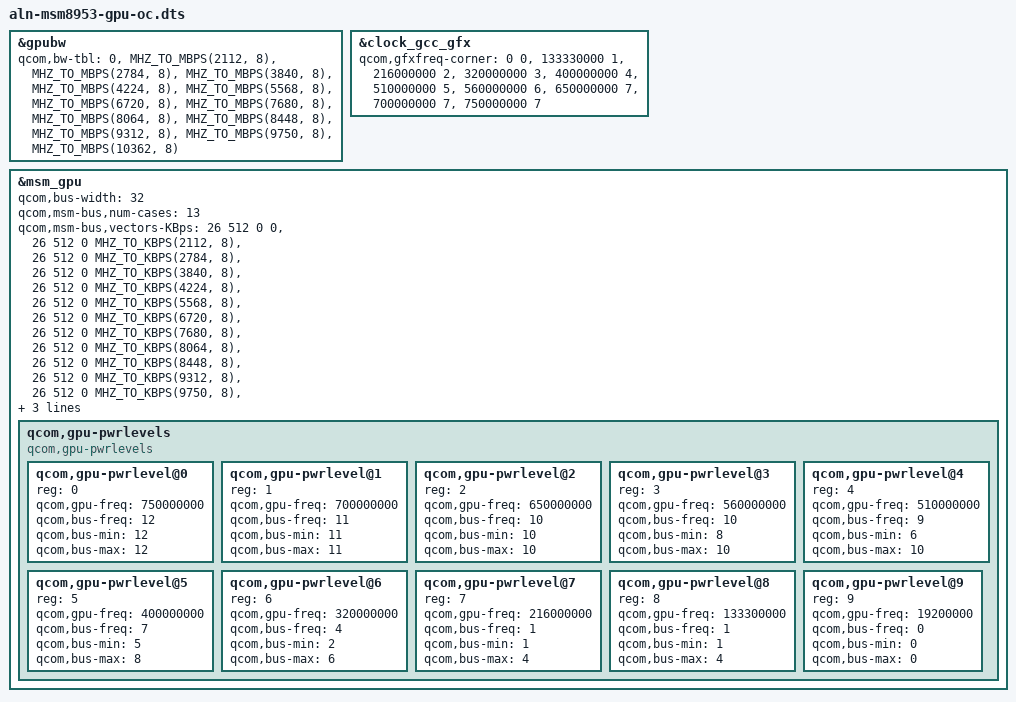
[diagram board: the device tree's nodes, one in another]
/*
 * Copyright (c) 2015-2017, The Linux Foundation. All rights reserved.
 * Copyright (C) 2019 XiaoMi, Inc.
 *
 * This program is free software; you can redistribute it and/or modify
 * it under the terms of the GNU General Public License version 2 and
 * only version 2 as published by the Free Software Foundation.
 *
 * This program is distributed in the hope that it will be useful,
 * but WITHOUT ANY WARRANTY; without even the implied warranty of
 * MERCHANTABILITY or FITNESS FOR A PARTICULAR PURPOSE.  See the
 * GNU General Public License for more details.
 */

/dts-v1/;

#define MHZ_TO_MBPS(mhz, w) ((mhz * 1000000 * w) / (10240 * 1024))
#define MHZ_TO_KBPS(mhz, w) ((mhz * 1000000 * w) / (10000))

&gpubw {
	/delete-node/qcom,bw-tbl;

	qcom,bw-tbl =
		< 0    >, /*  off */
		< MHZ_TO_MBPS(2112, 8) >, /* 1. 1611 DDR:211.20 MHz BIMC: 105.60 MHz */
		< MHZ_TO_MBPS(2784, 8) >, /* 2. 2124 DDR:278.40 MHz BIMC: 139.20 MHz */
		< MHZ_TO_MBPS(3840, 8) >, /* 3. 2929 DDR:384.00 MHz BIMC: 192.00 MHz */
		< MHZ_TO_MBPS(4224, 8) >, /* 4. 3222 DDR:422.40 MHz BIMC: 211.20 MHz */
		< MHZ_TO_MBPS(5568, 8) >, /* 5. 4248 DDR:556.80 MHz BIMC: 278.40 MHz */
		< MHZ_TO_MBPS(6720, 8) >, /* 6. 5126 DDR:672.00 MHz BIMC: 336.00 MHz */
		< MHZ_TO_MBPS(7680, 8) >, /* 7. 5859 DDR:768.00 MHz BIMC: 384.00 MHz */
		< MHZ_TO_MBPS(8064, 8) >, /* 8. 6152 DDR:806.40 MHz BIMC: 403.20 MHz */
		< MHZ_TO_MBPS(8448, 8) >, /* 9. 6445 DDR:844.80 MHz BIMC: 422.40 MHz */
		< MHZ_TO_MBPS(9312, 8) >, /*10. 7104 DDR:931.20 MHz BIMC: 465.60 MHz */
		< MHZ_TO_MBPS(9750, 8) >, /*11. */
		< MHZ_TO_MBPS(10362, 8) >; /*12. */
};

&clock_gcc_gfx {
	qcom,gfxfreq-corner =
		 <         0   0 >,
		 < 133330000   1 >,  /* Min SVS   */
		 < 216000000   2 >,  /* Low SVS   */
		 < 320000000   3 >,  /* SVS       */
		 < 400000000   4 >,  /* SVS Plus  */
		 < 510000000   5 >,  /* NOM       */
		 < 560000000   6 >,  /* Nom Plus  */
		 < 650000000   7 >,  /* Turbo     */
		 < 700000000   7 >,  /* Turbo     */
		 < 750000000   7 >;  /* Turbo     */
};

&msm_gpu {

	qcom,bus-width = <32>;
	qcom,msm-bus,num-cases = <13>;
	/delete-node/qcom,msm-bus,vectors-KBps;

	qcom,msm-bus,vectors-KBps =
				<26 512 0 0>,	     /*  off          */
				<26 512 0 MHZ_TO_KBPS(2112, 8)>, /* 1. 211.20 MHz */
				<26 512 0 MHZ_TO_KBPS(2784, 8)>, /* 2. 278.40 MHz */
				<26 512 0 MHZ_TO_KBPS(3840, 8)>, /* 3. 384.00 MHz */
				<26 512 0 MHZ_TO_KBPS(4224, 8)>, /* 4. 422.40 MHz */
				<26 512 0 MHZ_TO_KBPS(5568, 8)>, /* 5. 556.80 MHz */
				<26 512 0 MHZ_TO_KBPS(6720, 8)>, /* 6. 672.00 MHz */
				<26 512 0 MHZ_TO_KBPS(7680, 8)>, /* 7. 768.00 MHz */
				<26 512 0 MHZ_TO_KBPS(8064, 8)>, /* 8. 806.40 MHz */
				<26 512 0 MHZ_TO_KBPS(8448, 8)>, /* 9. 844.80 MHz */
				<26 512 0 MHZ_TO_KBPS(9312, 8)>, /*10. 931.20 MHz */
				<26 512 0 MHZ_TO_KBPS(9750, 8)>, /* 11. 975.00 MHz */
				<26 512 0 MHZ_TO_KBPS(10362, 8)>; /* 12. 1036.20 MHz*/
				
	qcom,ca-target-pwrlevel = <3>;
	qcom,initial-pwrlevel = <6>;
	/delete-node/qcom,gpu-pwrlevels;

	/* Power levels */
	qcom,gpu-pwrlevels {
		#address-cells = <1>;
		#size-cells = <0>;

		compatible = "qcom,gpu-pwrlevels";
		/* TURBO LD0 */
		qcom,gpu-pwrlevel@0 {
			reg = <0>;
			qcom,gpu-freq = <750000000>;
			qcom,bus-freq = <12>;
			qcom,bus-min = <12>;
			qcom,bus-max = <12>;
		};

		qcom,gpu-pwrlevel@1 {
			reg = <1>;
			qcom,gpu-freq = <700000000>;
			qcom,bus-freq = <11>;
			qcom,bus-min = <11>;
			qcom,bus-max = <11>;
		};

		/* TURBO */
		qcom,gpu-pwrlevel@2 {
			reg = <2>;
			qcom,gpu-freq = <650000000>;
			qcom,bus-freq = <10>;
			qcom,bus-min = <10>;
			qcom,bus-max = <10>;
		};

		/* NOM+ */
		qcom,gpu-pwrlevel@3 {
			reg = <3>;
			qcom,gpu-freq = <560000000>;
			qcom,bus-freq = <10>;
			qcom,bus-min = <8>;
			qcom,bus-max = <10>;
		};

		/* NOM */
		qcom,gpu-pwrlevel@4 {
			reg = <4>;
			qcom,gpu-freq = <510000000>;
			qcom,bus-freq = <9>;
			qcom,bus-min = <6>;
			qcom,bus-max = <10>;
		};

		/* SVS+ */
		qcom,gpu-pwrlevel@5 {
			reg = <5>;
			qcom,gpu-freq = <400000000>;
			qcom,bus-freq = <7>;
			qcom,bus-min = <5>;
			qcom,bus-max = <8>;
		};

		/* SVS */
		qcom,gpu-pwrlevel@6 {
			reg = <6>;
			qcom,gpu-freq = <320000000>;
			qcom,bus-freq = <4>;
			qcom,bus-min = <2>;
			qcom,bus-max = <6>;
		};

		/* Low SVS */
		qcom,gpu-pwrlevel@7 {
			reg = <7>;
			qcom,gpu-freq = <216000000>;
			qcom,bus-freq = <1>;
			qcom,bus-min = <1>;
			qcom,bus-max = <4>;
		};

		qcom,gpu-pwrlevel@8 {
			reg = <8>;
			qcom,gpu-freq = <133300000>;
			qcom,bus-freq = <1>;
			qcom,bus-min = <1>;
			qcom,bus-max = <4>;
		};
		/* XO */
		qcom,gpu-pwrlevel@9 {
			reg = <9>;
			qcom,gpu-freq = <19200000>;
			qcom,bus-freq = <0>;
			qcom,bus-min = <0>;
			qcom,bus-max = <0>;
		};
	};
}; 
